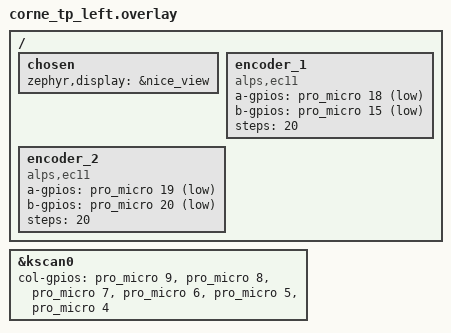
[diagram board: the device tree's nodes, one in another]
#include "corne_tp.dtsi"

/ {
    chosen {
        zephyr,display = &nice_view;
    };
    encoder_1: encoder_1 {
        compatible = "alps,ec11";
        a-gpios = <&pro_micro 18 (GPIO_ACTIVE_LOW | GPIO_PULL_UP)>;
        b-gpios = <&pro_micro 15 (GPIO_ACTIVE_LOW | GPIO_PULL_UP)>;
        steps = <20>;
    };
    encoder_2: encoder_2 {
        compatible = "alps,ec11";
        a-gpios = <&pro_micro 19 (GPIO_ACTIVE_LOW | GPIO_PULL_UP)>;
        b-gpios = <&pro_micro 20 (GPIO_ACTIVE_LOW | GPIO_PULL_UP)>;
        steps = <20>;
    };
};

&kscan0 {
    col-gpios
        = <&pro_micro 9 GPIO_ACTIVE_HIGH>
        , <&pro_micro 8 GPIO_ACTIVE_HIGH>
        , <&pro_micro 7 GPIO_ACTIVE_HIGH>
        , <&pro_micro 6 GPIO_ACTIVE_HIGH>
        , <&pro_micro 5 GPIO_ACTIVE_HIGH>
        , <&pro_micro 4 GPIO_ACTIVE_HIGH>
        ;
};
